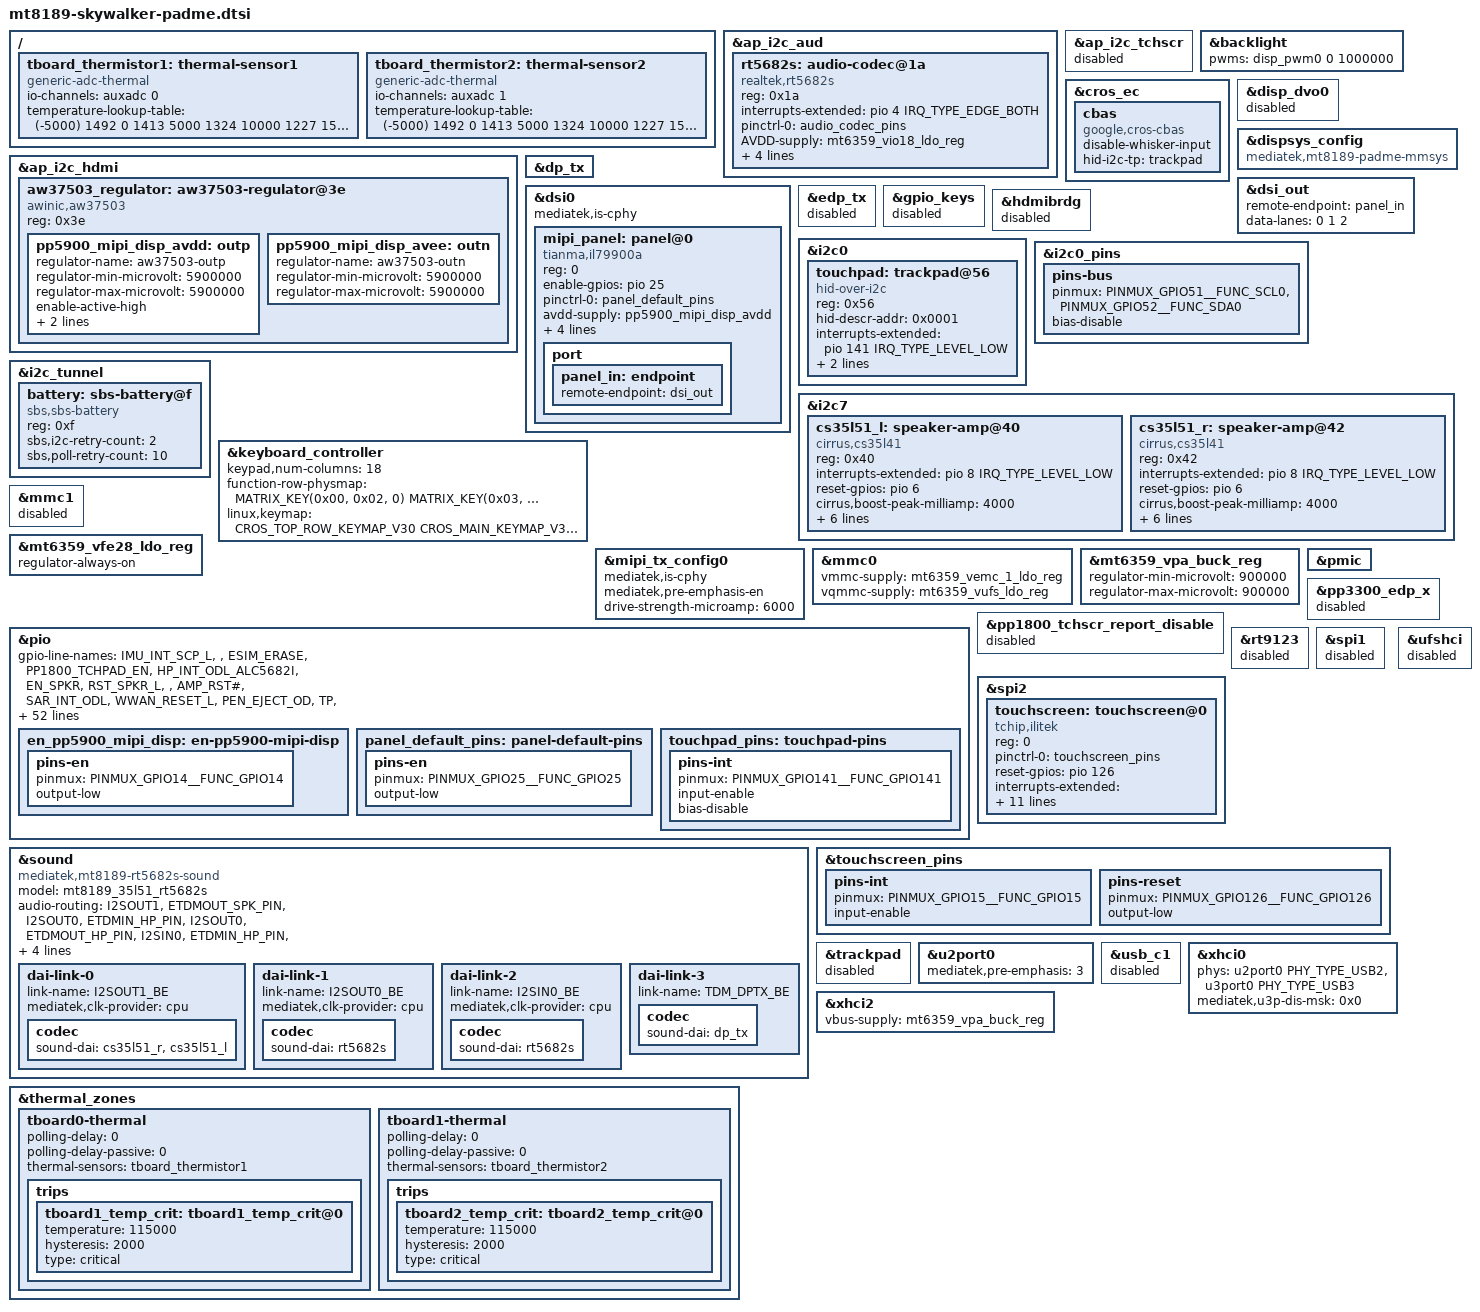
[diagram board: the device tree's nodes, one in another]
// SPDX-License-Identifier: (GPL-2.0 OR MIT)
/*
 * Copyright (C) 2025 Google Inc.
 */
/dts-v1/;
#include "mt8189-skywalker.dtsi"

/ {
	tboard_thermistor1: thermal-sensor1 {
		compatible = "generic-adc-thermal";
		#thermal-sensor-cells = <0>;
		io-channels = <&auxadc 0>;
		io-channel-names = "sensor-channel";
		temperature-lookup-table = <    (-5000) 1492
						0 1413
						5000 1324
						10000 1227
						15000 1121
						20000 1017
						25000 900
						30000 797
						35000 698
						40000 606
						45000 522
						50000 449
						55000 383
						60000 327
						65000 278
						70000 236
						75000 201
						80000 171
						85000 145
						90000 163
						95000 124
						100000 91
						105000 78
						110000 67
						115000 58
						120000 50
						125000 44>;
	};

	tboard_thermistor2: thermal-sensor2 {
		compatible = "generic-adc-thermal";
		#thermal-sensor-cells = <0>;
		io-channels = <&auxadc 1>;
		io-channel-names = "sensor-channel";
		temperature-lookup-table = <    (-5000) 1492
						0 1413
						5000 1324
						10000 1227
						15000 1121
						20000 1017
						25000 900
						30000 797
						35000 698
						40000 606
						45000 522
						50000 449
						55000 383
						60000 327
						65000 278
						70000 236
						75000 201
						80000 171
						85000 145
						90000 163
						95000 124
						100000 91
						105000 78
						110000 67
						115000 58
						120000 50
						125000 44>;
	};
};

&ap_i2c_aud {
	/delete-node/ audio-codec@1a;

	rt5682s: audio-codec@1a {
		compatible = "realtek,rt5682s";
		reg = <0x1a>;
		interrupts-extended = <&pio 4 IRQ_TYPE_EDGE_BOTH>;
		pinctrl-names = "default";
		pinctrl-0 = <&audio_codec_pins>;
		#sound-dai-cells = <0>;

		AVDD-supply = <&mt6359_vio18_ldo_reg>;
		DBVDD-supply = <&mt6359_vio18_ldo_reg>;
		LDO1-IN-supply = <&mt6359_vio18_ldo_reg>;
		MICVDD-supply = <&pp3300_z1>;
		realtek,jd-src = <1>;
		status = "okay";
	};
};

&ap_i2c_hdmi {
	aw37503_regulator: aw37503-regulator@3e {
		compatible = "awinic,aw37503";
		reg = <0x3e>;

		pp5900_mipi_disp_avdd: outp {
			regulator-name = "aw37503-outp";
			regulator-min-microvolt = <5900000>;
			regulator-max-microvolt = <5900000>;
			enable-active-high;
			enable-gpios = <&pio 14 GPIO_ACTIVE_HIGH>;
			pinctrl-names = "default";
			pinctrl-0 = <&en_pp5900_mipi_disp>;
		};

		pp5900_mipi_disp_avee: outn {
			regulator-name = "aw37503-outn";
			regulator-min-microvolt = <5900000>;
			regulator-max-microvolt = <5900000>;
		};
	};
};

&ap_i2c_tchscr {
	status = "disabled";
};

&backlight {
	pwms = <&disp_pwm0 0 1000000>;
};

&cros_ec {
	cbas {
		compatible = "google,cros-cbas";
		disable-whisker-input;
		hid-i2c-tp = <&trackpad>;
	};
};

&disp_dvo0 {
	status = "disabled";
};

&dispsys_config {
	compatible = "mediatek,mt8189-padme-mmsys", "syscon";
};

&dp_tx {
	/delete-property/ mediatek,phy-flip-gpios;
};

&dsi0 {
	#address-cells = <1>;
	#size-cells = <0>;
	mediatek,is-cphy;

	mipi_panel: panel@0 {
		compatible = "tianma,il79900a";
		reg = <0>;
		enable-gpios = <&pio 25 GPIO_ACTIVE_HIGH>;
		pinctrl-names = "default";
		pinctrl-0 = <&panel_default_pins>;
		avdd-supply = <&pp5900_mipi_disp_avdd>;
		avee-supply = <&pp5900_mipi_disp_avee>;
		pp1800-supply = <&mt6359_vcn18_ldo_reg>;
		backlight = <&backlight>;
		rotation = <270>;
		status = "okay";

		port {
			panel_in: endpoint {
				remote-endpoint = <&dsi_out>;
			};
		};
	};

};

&dsi_out {
	remote-endpoint = <&panel_in>;
	data-lanes = <0 1 2>;
};

&edp_tx {
	status = "disabled";
};

&gpio_keys {
	status = "disabled";
};

&hdmibrdg {
	status = "disabled";
};

&i2c0 {
	touchpad: trackpad@56 {
		compatible = "hid-over-i2c";
		reg = <0x56>;
		hid-descr-addr = <0x0001>;
		interrupts-extended = <&pio 141 IRQ_TYPE_LEVEL_LOW>;
		pinctrl-names = "default";
		pinctrl-0 = <&touchpad_pins>;
		wakeup-source;
		status = "okay";
	};
};

&i2c0_pins {
	pins-bus {
		pinmux = <PINMUX_GPIO51__FUNC_SCL0>,
			 <PINMUX_GPIO52__FUNC_SDA0>;
		bias-disable;
	};
};

&i2c7 {
	cs35l51_l: speaker-amp@40 {
		compatible = "cirrus,cs35l41";
		reg = <0x40>;
		interrupts-extended = <&pio 8 IRQ_TYPE_LEVEL_LOW>;
		reset-gpios = <&pio 6 GPIO_ACTIVE_HIGH>;
		cirrus,boost-peak-milliamp = <4000>;
		cirrus,boost-ind-nanohenry = <1000>;
		cirrus,boost-cap-microfarad = <15>;
		cirrus,asp-sdout-hiz = <3>;
		cirrus,gpio2-src-select = <2>;
		cirrus,gpio2-output-enable;
		cirrus,subsystem-id = "104315ee";
		#sound-dai-cells = <0>;
	};

	cs35l51_r: speaker-amp@42 {
		compatible = "cirrus,cs35l41";
		reg = <0x42>;
		interrupts-extended = <&pio 8 IRQ_TYPE_LEVEL_LOW>;
		reset-gpios = <&pio 6 GPIO_ACTIVE_HIGH>;
		cirrus,boost-peak-milliamp = <4000>;
		cirrus,boost-ind-nanohenry = <1000>;
		cirrus,boost-cap-microfarad = <15>;
		cirrus,asp-sdout-hiz = <3>;
		cirrus,gpio2-src-select = <2>;
		cirrus,gpio2-output-enable;
		cirrus,subsystem-id = "104315ee";
		#sound-dai-cells = <0>;
	};
};

&i2c_tunnel {
	/delete-node/ sbs-battery@b;
	battery: sbs-battery@f {
		compatible = "sbs,sbs-battery";
		reg = <0xf>;
		sbs,i2c-retry-count = <2>;
		sbs,poll-retry-count = <10>;
	};
};

&keyboard_controller {
	keypad,num-columns = <18>;

	function-row-physmap = <
		MATRIX_KEY(0x00, 0x02, 0)        /* T1 */
		MATRIX_KEY(0x03, 0x02, 0)        /* T2 */
		MATRIX_KEY(0x02, 0x02, 0)        /* T3 */
		MATRIX_KEY(0x01, 0x02, 0)        /* T4 */
		MATRIX_KEY(0x04, 0x04, 0)        /* T5 */
		MATRIX_KEY(0x02, 0x04, 0)        /* T6 */
		MATRIX_KEY(0x01, 0x04, 0)        /* T7 */
		MATRIX_KEY(0x02, 0x0b, 0)        /* T8 */
		MATRIX_KEY(0x01, 0x09, 0)        /* T9 */
		MATRIX_KEY(0x00, 0x04, 0)        /* T10 */
		MATRIX_KEY(0x00, 0x01, 0)        /* T11 */
		MATRIX_KEY(0x01, 0x05, 0)        /* T12 */
		MATRIX_KEY(0x03, 0x05, 0)        /* T13 */
		MATRIX_KEY(0x00, 0x0b, 0)        /* T14 */
	>;

	linux,keymap = <
		CROS_TOP_ROW_KEYMAP_V30
		CROS_MAIN_KEYMAP_V30
		MATRIX_KEY(0x00, 0x02, KEY_BACK)                 /* T1 */
		MATRIX_KEY(0x03, 0x02, KEY_REFRESH)              /* T2 */
		MATRIX_KEY(0x02, 0x02, KEY_ZOOM)                 /* T3 */
		MATRIX_KEY(0x01, 0x02, KEY_SCALE)                /* T4 */
		MATRIX_KEY(0x04, 0x04, KEY_SYSRQ)                /* T5 */
		MATRIX_KEY(0x02, 0x04, KEY_BRIGHTNESSDOWN)       /* T6 */
		MATRIX_KEY(0x01, 0x04, KEY_BRIGHTNESSUP)         /* T7 */
		MATRIX_KEY(0x02, 0x0b, KEY_DICTATE)              /* T8 */
		MATRIX_KEY(0x01, 0x09, KEY_PLAYPAUSE)            /* T9 */
		MATRIX_KEY(0x00, 0x04, KEY_MICMUTE)              /* T10 */
		MATRIX_KEY(0x00, 0x01, KEY_MUTE)                 /* T11 */
		MATRIX_KEY(0x01, 0x05, KEY_VOLUMEDOWN)           /* T12 */
		MATRIX_KEY(0x03, 0x05, KEY_VOLUMEUP)             /* T13 */
		MATRIX_KEY(0x00, 0x0b, KEY_ACCESSIBILITY)        /* T14 */
		MATRIX_KEY(0x02, 0x0a, KEY_YEN)                  /* JP ￥*/
		MATRIX_KEY(0x04, 0x0a, KEY_FN)                   /* FN ￥*/
		MATRIX_KEY(0x06, 0x0a, KEY_BACKSLASH)            /*UK #*/
		MATRIX_KEY(0x02, 0x07, KEY_102ND)                /*UK \\*/
	>;
};

&mipi_tx_config0 {
	mediatek,is-cphy;
	mediatek,pre-emphasis-en;

	drive-strength-microamp = <6000>;
};

&mmc0 {
	vmmc-supply = <&mt6359_vemc_1_ldo_reg>;
	vqmmc-supply = <&mt6359_vufs_ldo_reg>;

	status = "okay";
};

&mmc1 {
	status = "disabled";
};

&mt6359_vpa_buck_reg {
	regulator-min-microvolt = <900000>;
	regulator-max-microvolt = <900000>;
};

/* Use PMIC VFE28 for WFC 2.8V AF power supply */
&mt6359_vfe28_ldo_reg {
	regulator-always-on;
};

&pio{
	/* 182 lines */
	gpio-line-names =
		"IMU_INT_SCP_L",		/* 0 */
		"",
		"ESIM_ERASE",
		"PP1800_TCHPAD_EN",
		"HP_INT_ODL_ALC5682I",
		"EN_SPKR",
		"RST_SPKR_L",
		"",
		"AMP_RST#",
		"SAR_INT_ODL",
		"WWAN_RESET_L",			/* 10 */
		"PEN_EJECT_OD",
		"TP",
		"MIPI_BL_EN_1V8",
		"EN_PP6000_MIPI_DISP",
		"TCHSCR_INT_1V8_ODL",
		"AP_FLASH_WP_L",
		"EC_AP_DPOC_EN_ODL",
		"",
		"",
		"",				/* 20 */
		"",
		"",
		"",
		"",
		"EDP_RESET",
		"",
		"EC_AP_DP_HPD_L",
		"",
		"BL_PWM_1V8",
		"",		                /* 30 */
		"UART_AP_TX_GSC_DBG_RX",
		"UART_GSC_DBG_TX_AP_RX",
		"AP_UART1_TXD",
		"AP_UART1_RXD",
		"AP_UART2_TXD",
		"AP_UART2_RXD",
		"AP_UART3_TXD",
		"AP_UART3_RXD",
		"AP_JTAG_TMS",
		"AP_JTAG_TCK",			/* 40 */
		"AP_JTAG_TDI",
		"AP_JTAG_TDO",
		"AP_JTAG_TRST_L",
		"AP_KPCOL0",
		"TP",
		"TP",
		"TP",
		"PCIE_WLAN_WAKE_OBFF_1V8_ODL",
		"PCIE_WLAN_RST_1V8_L",
		"PCIE_WLAN_CLKREQ_1V8_ODL",	/* 50 */
		"SCP_I2C_SENSOR_SCL_1V8",
		"SCP_I2C_SENSOR_SDA_1V8",
		"TP",
		"TP",
		"AP_I2C_COD_SCL_ALC5682I",
		"AP_I2C_COD_SDA_ALC5682I",
		"AP_I2C_TPM_SCL_1V8",
		"AP_I2C_TPM_SDA_1V8",
		"",
		"",	                        /* 60 */
		"AP_I2C_SAR_SCL_1V8",
		"AP_I2C_SAR_SDA_1V8",
		"AP_I2C_DISP_SCL_1V8",
		"AP_I2C_DISP_SDA_1V8",
		"AP_I2C_TCHPAD_SCL_1V8",
		"AP_I2C_TCHPAD_SDA_1V8",
		"TP",
		"TP",
		"SPI_AP_CS_EC_L",
		"SPI_AP_CLK_EC",		/* 70 */
		"SPI_AP_DO_EC_DI",
		"SPI_AP_DI_EC_DO",
		"TP",
		"TP",
		"TP",
		"TP",
		"SPI_AP_CS_TCHSCR_R",
		"SPI_AP_CLK_TCHSCR_R",
		"SPI_AP_DO_TCHSCR_DI",
		"",		               /* 80 */
		"",
		"",
		"",
		"",
		"",
		"",
		"",
		"PWRAP_SPI_CS_L",
		"PWRAP_SPI_CK",
		"PWRAP_SPI_MOSI",		/* 90 */
		"PWRAP_SPI_MISO",
		"SRCLKENA0",
		"SRCLKENA1",
		"SCP_VREQ_VAO",
		"AP_RTC_CLK32K",
		"AP_PMIC_WDTRST_L",
		"AUD_CLK_MOSI (Strap)",
		"AUD_SYNC_MOSI (Strap)",
		"AUD_DAT_MOSI0 (Strap)",
		"AUD_DAT_MOSI1 (Strap)",	/* 100 */
		"AUD_DAT_MISO0 (Strap)",
		"AUD_DAT_MISO1 (Strap)",
		"TP",
		"TP",
		"TP",
		"I2S_HP_DI",
		"I2S_HP_MCK",
		"I2S_HP_BCK",
		"I2S_HP_LRCK",
		"I2S_HP_DO",			/* 110 */
		"I2S_SPKR_MCK",
		"I2S_SPKR_BCK_R",
		"I2S_SPKR_LRCK_R",
		"I2S_SPKR_DO_R",
		"PCM_HDMI_CLK",
		"PCM_HDMI_SYNC",
		"TP",
		"PCM_HDMI_DO",
		"DMIC0_CLK",
		"DMIC0_DATA",			/* 120 */
		"EN_PP3300_WWAN_X",
		"DMIC1_CLK",
		"DMIC1_DATA",
		"WWAN_SAR_DETECT_L",
		"",
		"TCHSCR_RST_1V8_L",
		"",
		"",
		"TP",
		"I2S_SPKR_DI_0",			/* 130 */
		"AP_XHCI_INIT_DONE",
		"EC_AP_INT_ODL",
		"TP",
		"TP",
		"",
		"",
		"AP_EC_WARM_RST_REQ",
		"GSC_AP_INT_ODL",
		"",
		"AP_SUSPEND_L ",		/* 140 */
		"EC_AP_RSVD0_ODL",
		"EC_AP_RSVD1_ODL",
		"MT6319B_INT",
		"MT6319C_INT",
		"BT_KILL_1V8_L",
		"WIFI_KILL_1V8_L",
		"WWAN_PWR_OFF_L",
		"WWAN_W_DISABLE_L",
		"",
		"SPI_AP_CLK_BIOS",		/* 150 */
		"SPI_AP_CS_BIOS_L",
		"SPI_AP_DO_BIOS_DI",
		"SPI_AP_DI_BIOS_DO",
		"TP",
		"TP",
		"",
		"",
		"",
		"",
		"",				/* 160 */
		"",
		"",
		"",
		"",
		"",
		"",
		"",
		"",
		"",
		"",			/* 170 */
		"",
		"",
		"",
		"",
		"",
		"",
		"",
		"",
		"",
		"SPMI_SCL",			/* 180 */
		"SPMI_SDA",
		"EMI_RESET_N";

	en_pp5900_mipi_disp: en-pp5900-mipi-disp {
		pins-en {
			pinmux = <PINMUX_GPIO14__FUNC_GPIO14>;
			output-low;
		};
	};

	panel_default_pins: panel-default-pins {
		pins-en {
			pinmux = <PINMUX_GPIO25__FUNC_GPIO25>;
			output-low;
		};
	};

	touchpad_pins: touchpad-pins {
		pins-int {
			pinmux = <PINMUX_GPIO141__FUNC_GPIO141>;
			input-enable;
			bias-disable;
		};
	};
};

&pmic {
	/delete-node/ mt6359codec;
};

&pp1800_tchscr_report_disable {
	status = "disabled";
};

&pp3300_edp_x {
	status = "disabled";
};

&rt9123 {
	status = "disabled";
};

&sound {
	compatible = "mediatek,mt8189-rt5682s-sound";
	model = "mt8189_35l51_rt5682s";
	status = "okay";

	audio-routing = "I2SOUT1", "ETDMOUT_SPK_PIN",
			"I2SOUT0", "ETDMIN_HP_PIN",
			"I2SOUT0", "ETDMOUT_HP_PIN",
			"I2SIN0", "ETDMIN_HP_PIN",
			"I2SIN0", "ETDMOUT_HP_PIN",
			"IN1P", "Headset Mic",
			"PCM 0 Playback", "ETDMOUT_HDMI_PIN",
			"AP DMIC Capture", "AP_DMIC0_PIN",
			"AP DMIC CH34 Capture", "AP_DMIC1_PIN";

	/delete-node/ dai-link-6;

	dai-link-0 {
		link-name = "I2SOUT1_BE";
		mediatek,clk-provider = "cpu";

		codec {
			sound-dai = <&cs35l51_r>,
				    <&cs35l51_l>;
		};
	};

	dai-link-1 {
		link-name = "I2SOUT0_BE";
		mediatek,clk-provider = "cpu";

		codec {
			sound-dai = <&rt5682s>;
		};
	};

	dai-link-2 {
		link-name = "I2SIN0_BE";
		mediatek,clk-provider = "cpu";

		codec {
			sound-dai = <&rt5682s>;
		};
	};

	dai-link-3 {
		link-name = "TDM_DPTX_BE";

		codec {
			sound-dai = <&dp_tx>;
		};
	};
};

&spi1 {
	status = "disabled";
};

&spi2 {
	touchscreen: touchscreen@0 {
		compatible = "tchip,ilitek";
		reg = <0>;
		pinctrl-names = "default";
		pinctrl-0 = <&touchscreen_pins>;
		reset-gpios = <&pio 126 GPIO_ACTIVE_HIGH>;
		interrupts-extended = <&pio 15 IRQ_TYPE_EDGE_FALLING>;
		spi-max-frequency = <3000000>;
		spi-cs-setup-delay-ns = <30>;
		panel = <&mipi_panel>;

		input-report-header-address = <0x001000>;
		input-report-body-address   = <0x001000>;
		output-report-address       = <0x002000>;
		read-opcode                 = <0x83>;
		write-opcode                = <0x82>;
		post-power-on-delay-ms      = <0>;
		minimal-reset-delay-ms      = <10>;
		status = "okay";
	};
};

&thermal_zones {
	tboard0-thermal {
		polling-delay = <0>; /* milliseconds */
		polling-delay-passive = <0>; /* milliseconds */
		thermal-sensors = <&tboard_thermistor1>;

		trips {
			tboard1_temp_crit: tboard1_temp_crit@0 {
				temperature = <115000>;
				hysteresis = <2000>;
				type = "critical";
			};
		};
	};

	tboard1-thermal {
		polling-delay = <0>; /* milliseconds */
		polling-delay-passive = <0>; /* milliseconds */
		thermal-sensors = <&tboard_thermistor2>;

		trips {
			tboard2_temp_crit: tboard2_temp_crit@0 {
				temperature = <115000>;
				hysteresis = <2000>;
				type = "critical";
			};
		};
	};
};

&touchscreen_pins {
	pins-int {
		pinmux = <PINMUX_GPIO15__FUNC_GPIO15>;
		/delete-property/ bias-pull-up;
		input-enable;
	};

	pins-reset {
		pinmux = <PINMUX_GPIO126__FUNC_GPIO126>;
		/delete-property/ output-high;
		output-low;
	};
};

&trackpad {
	status = "disabled";
};

&u2port0 {
	mediatek,pre-emphasis = <3>;
};

&ufshci {
	status = "disabled";
};

&usb_c1 {
	status = "disabled";
};

&xhci0 {
	phys = <&u2port0 PHY_TYPE_USB2>,
	       <&u3port0 PHY_TYPE_USB3>;
	mediatek,u3p-dis-msk = <0x0>;
	status = "okay";
};

&xhci2 {
	vbus-supply = <&mt6359_vpa_buck_reg>;
};
